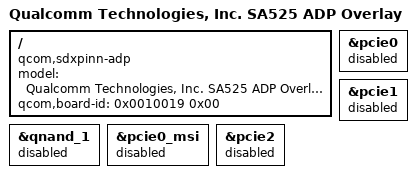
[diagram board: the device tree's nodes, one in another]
/dts-v1/;
/plugin/;

#include "sa525m-adp.dtsi"

/ {
	model = "Qualcomm Technologies, Inc. SA525 ADP Overlay";
	compatible = "qcom,sdxpinn-adp",
		"qcom,sdxpinn", "qcom,adp";
	qcom,board-id = <0x0010019 0x00>;
};

&qnand_1 {
	status = "disabled";
};

&pcie0 {
	status = "disabled";
};

&pcie0_msi {
	status = "disabled";
};

&pcie1 {
	status = "disabled";
};

&pcie2 {
	status = "disabled";
};
